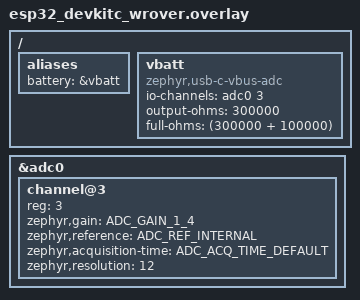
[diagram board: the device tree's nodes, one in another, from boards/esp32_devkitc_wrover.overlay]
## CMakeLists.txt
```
# SPDX-License-Identifier: Apache-2.0

cmake_minimum_required(VERSION 3.20.0)

find_package(Zephyr REQUIRED HINTS $ENV{ZEPHYR_BASE})
project(vbatt)

target_sources(app PRIVATE src/main.c)
```

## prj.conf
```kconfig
CONFIG_USBC_VBUS_ADC=y
CONFIG_USBC_VBUS_DRIVER=y

CONFIG_GPIO=y
CONFIG_ADC=y
```

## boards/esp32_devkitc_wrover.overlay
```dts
/*
 * Copyright (c) 2023 Mark Kettner <mark@kettner.io>
 *
 * SPDX-License-Identifier: Apache-2.0
 */

/ {
	aliases {
		battery = &vbatt;
	};

	vbatt: vbatt {
		compatible = "zephyr,usb-c-vbus-adc";
		status = "okay";
		io-channels = <&adc0 3>;
		output-ohms = <300000>;
		full-ohms = <(300000 + 100000)>;
	};

};

&adc0 {
	status = "okay";
	#address-cells = <1>;
	#size-cells = <0>;

	channel@3 {
		reg = <3>;
		zephyr,gain = "ADC_GAIN_1_4";
		zephyr,reference = "ADC_REF_INTERNAL";
		zephyr,acquisition-time = <ADC_ACQ_TIME_DEFAULT>;
		zephyr,resolution = <12>;
	};
};
```

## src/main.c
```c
/*
 * Copyright (c) 2023 Mark Kettner <mark@kettner.io>
 *
 * SPDX-License-Identifier: Apache-2.0
 */

#include <zephyr/device.h>
#include <zephyr/drivers/usb_c/usbc_vbus.h>
#include <zephyr/kernel.h>

#define BAT_NODE DT_ALIAS(battery)
static const struct device *bat_dev = DEVICE_DT_GET(BAT_NODE);

int main(void)
{
	int rc = 0;
	int mea;

	for (;;) {
		usbc_vbus_measure(bat_dev, &mea);
		printf("bat=%i.%iV", mea / 100, mea % 100);
		k_sleep(K_SECONDS(5));
	}
}
```
